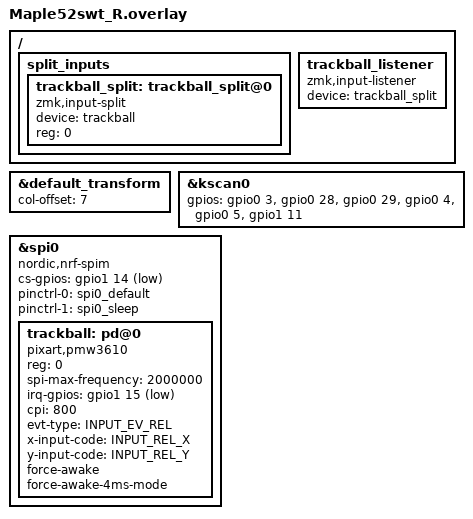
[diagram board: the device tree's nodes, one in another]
/*
 * Copyright (c) 2020 Pete Johanson
 *
 * SPDX-License-Identifier: MIT
 */

#include <dt-bindings/zmk/bt.h>
#include <input/processors.dtsi>
#include <dt-bindings/zmk/input_transform.h>
#include "Maple52swt.dtsi"

&default_transform {
    col-offset = <7>;
};

&kscan0 {
        gpios
          = <&gpio0  3 GPIO_ACTIVE_HIGH>
          , <&gpio0 28 GPIO_ACTIVE_HIGH>
          , <&gpio0 29 GPIO_ACTIVE_HIGH>
          , <&gpio0  4 GPIO_ACTIVE_HIGH>
          , <&gpio0  5 GPIO_ACTIVE_HIGH>
          , <&gpio1 11 GPIO_ACTIVE_HIGH>
          ;
};

&spi0 {
    status = "okay";
    cs-gpios = <&gpio1 14 GPIO_ACTIVE_LOW>;
    pinctrl-0 = <&spi0_default>;
    pinctrl-1 = <&spi0_sleep>;
    pinctrl-names = "default", "sleep";
    compatible = "nordic,nrf-spim";

    trackball: pd@0 {
        status = "okay";
        compatible = "pixart,pmw3610";
        reg = <0>;
        spi-max-frequency = <2000000>;
        irq-gpios = <&gpio1 15 (GPIO_ACTIVE_LOW | GPIO_PULL_UP)>;
        cpi = <800>;
        evt-type = <INPUT_EV_REL>;
        x-input-code = <INPUT_REL_X>;
        y-input-code = <INPUT_REL_Y>;
        force-awake;
        force-awake-4ms-mode;
    };
};

/ {
    split_inputs {
        #address-cells = <1>;
        #size-cells = <0>;

        trackball_split: trackball_split@0 {
            compatible = "zmk,input-split";
            device = <&trackball>;
            reg = <0>;
        };
    };

    trackball_listener: trackball_listener {
        compatible = "zmk,input-listener";
        device = <&trackball_split>;
    };
};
